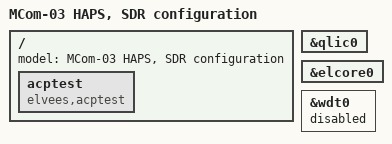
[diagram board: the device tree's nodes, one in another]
// SPDX-License-Identifier: GPL-2.0+
/*
 * Copyright 2020 RnD Center "ELVEES", JSC
 */

/dts-v1/;

#include "mcom03-haps-common.dtsi"

/ {
	model = "MCom-03 HAPS, SDR configuration";

	acptest {
		compatible = "elvees,acptest";
	};
};

&qlic0 {
	status = "okay";
};

&elcore0 {
	status = "okay";
};

&wdt0 {
	status = "disabled";
};
